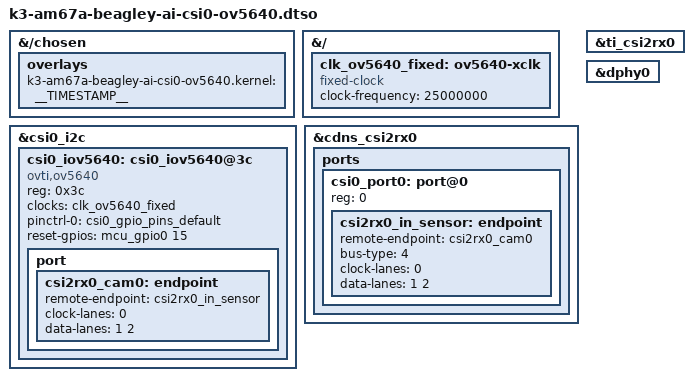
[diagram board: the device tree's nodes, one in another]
// SPDX-License-Identifier: GPL-2.0
/**
 * DT Overlay for RPi 7inch touchscreen panel interfaced with DSI on
 *
 * RPi DSI Panel: https://www.raspberrypi.com/products/raspberry-pi-touch-display/
 *
 * Copyright (C) 2023 Texas Instruments Incorporated - https://www.ti.com/
 */

/dts-v1/;
/plugin/;

#include <dt-bindings/gpio/gpio.h>
//#include "k3-pinctrl.h"

/*
 * Helper to show loaded overlays under: /proc/device-tree/chosen/overlays/
 */
&{/chosen} {
	overlays {
		k3-am67a-beagley-ai-csi0-ov5640.kernel = __TIMESTAMP__;
	};
};

&{/} {
	clk_ov5640_fixed: ov5640-xclk {
		compatible = "fixed-clock";
		#clock-cells = <0>;
		clock-frequency = <25000000>;
	};
};

&csi0_i2c {
	#address-cells = <1>;
	#size-cells = <0>;

	csi0_iov5640: csi0_iov5640@3c {
		status = "okay";
		compatible = "ovti,ov5640";
		reg = <0x3c>;

		clocks = <&clk_ov5640_fixed>;
		clock-names = "xclk";

		pinctrl-names = "default";
		pinctrl-0 = <&csi0_gpio_pins_default>;
		reset-gpios = <&mcu_gpio0 15 GPIO_ACTIVE_HIGH>;

		port {
			csi2rx0_cam0: endpoint {
				remote-endpoint = <&csi2rx0_in_sensor>;
				clock-lanes = <0>;
				data-lanes = <1 2>;
			};
		};
	};
};

&cdns_csi2rx0 {
	ports {
		#address-cells = <1>;
		#size-cells = <0>;

		csi0_port0: port@0 {
			reg = <0>;
			status = "okay";

			csi2rx0_in_sensor: endpoint {
				remote-endpoint = <&csi2rx0_cam0>;
				bus-type = <4>; /* CSI2 DPHY */
				clock-lanes = <0>;
				data-lanes = <1 2>;
			};
		};
	};
};

&ti_csi2rx0 {
	status = "okay";
};

&dphy0 {
	status = "okay";
};
